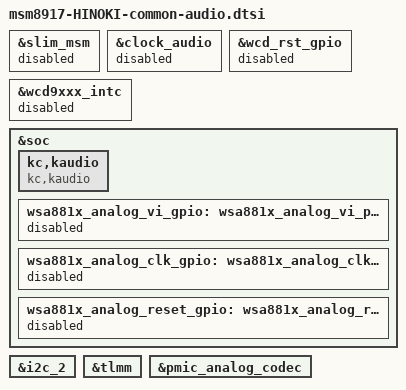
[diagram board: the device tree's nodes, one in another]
/*
 * This software is contributed or developed by KYOCERA Corporation.
 * (C) 2019 KYOCERA Corporation
 *
 * This program is free software; you can redistribute it and/or modify
 * it under the terms of the GNU General Public License version 2 and
 * only version 2 as published by the Free Software Foundation.
 *
 * This program is distributed in the hope that it will be useful,
 * but WITHOUT ANY WARRANTY; without even the implied warranty of
 * MERCHANTABILITY or FITNESS FOR A PARTICULAR PURPOSE.  See the
 * GNU General Public License for more details.
 */

&slim_msm {
	status = "disabled";
	/delete-node/ tasha_codec;
};

&clock_audio {
	status = "disabled";
};

&wcd_rst_gpio {
	status = "disabled";
	/delete-property/ qcom,cdc-rst-n-gpio;
};

&wcd9xxx_intc {
	status = "disabled";
};

&soc{
	/delete-node/ sound-9335;
	/delete-node/ eldo2;

	kc,kaudio {
		compatible = "kc,kaudio";
	};

	wsa881x_analog_vi_gpio: wsa881x_analog_vi_pctrl {
		status = "disabled";
	};

	wsa881x_analog_clk_gpio: wsa881x_analog_clk_pctrl {
		status = "disabled";
	};

	wsa881x_analog_reset_gpio: wsa881x_analog_reset_pctrl {
		status = "disabled";
	};
};

&i2c_2 {
	/delete-node/ wsa881x-i2c-codec@f;
	/delete-node/ wsa881x-i2c-codec@45;
};

&tlmm {
	/delete-node/ cross-conn-det;
	/delete-node/ pri-tlmm-lines;
	/delete-node/ pri-tlmm-ws-lines;
	/delete-node/ cdc_mclk2_pin;
};

&pmic_analog_codec {
	status = "okay";
};


